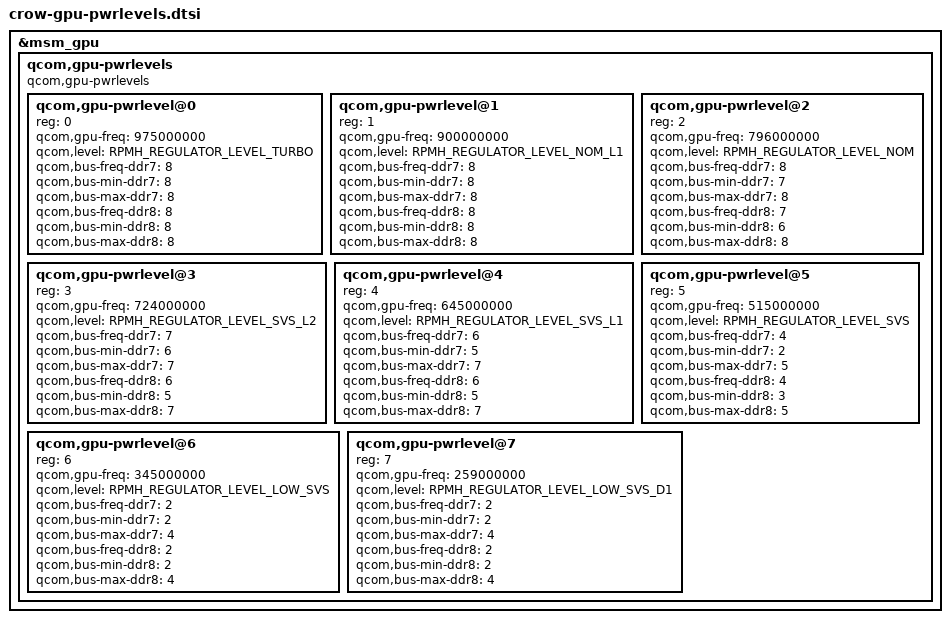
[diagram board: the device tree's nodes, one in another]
&msm_gpu {
	/* Power levels */
	qcom,gpu-pwrlevels {
		compatible="qcom,gpu-pwrlevels";

		#address-cells = <1>;
		#size-cells = <0>;

		qcom,gpu-pwrlevel@0 {
			reg = <0>;
			qcom,gpu-freq = <975000000>;
			qcom,level = <RPMH_REGULATOR_LEVEL_TURBO>;

			qcom,bus-freq-ddr7 = <8>;
			qcom,bus-min-ddr7 = <8>;
			qcom,bus-max-ddr7 = <8>;

			qcom,bus-freq-ddr8 = <8>;
			qcom,bus-min-ddr8 = <8>;
			qcom,bus-max-ddr8 = <8>;
		};

		qcom,gpu-pwrlevel@1 {
			reg = <1>;
			qcom,gpu-freq = <900000000>;
			qcom,level = <RPMH_REGULATOR_LEVEL_NOM_L1>;

			qcom,bus-freq-ddr7 = <8>;
			qcom,bus-min-ddr7 = <8>;
			qcom,bus-max-ddr7 = <8>;

			qcom,bus-freq-ddr8 = <8>;
			qcom,bus-min-ddr8 = <8>;
			qcom,bus-max-ddr8 = <8>;
		};

		qcom,gpu-pwrlevel@2 {
			reg = <2>;
			qcom,gpu-freq = <796000000>;
			qcom,level = <RPMH_REGULATOR_LEVEL_NOM>;

			qcom,bus-freq-ddr7 = <8>;
			qcom,bus-min-ddr7 = <7>;
			qcom,bus-max-ddr7 = <8>;

			qcom,bus-freq-ddr8 = <7>;
			qcom,bus-min-ddr8 = <6>;
			qcom,bus-max-ddr8 = <8>;
		};

		qcom,gpu-pwrlevel@3 {
			reg = <3>;
			qcom,gpu-freq = <724000000>;
			qcom,level = <RPMH_REGULATOR_LEVEL_SVS_L2>;

			qcom,bus-freq-ddr7 = <7>;
			qcom,bus-min-ddr7 = <6>;
			qcom,bus-max-ddr7 = <7>;

			qcom,bus-freq-ddr8 = <6>;
			qcom,bus-min-ddr8 = <5>;
			qcom,bus-max-ddr8 = <7>;
		};

		qcom,gpu-pwrlevel@4 {
			reg = <4>;
			qcom,gpu-freq = <645000000>;
			qcom,level = <RPMH_REGULATOR_LEVEL_SVS_L1>;

			qcom,bus-freq-ddr7 = <6>;
			qcom,bus-min-ddr7 = <5>;
			qcom,bus-max-ddr7 = <7>;

			qcom,bus-freq-ddr8 = <6>;
			qcom,bus-min-ddr8 = <5>;
			qcom,bus-max-ddr8 = <7>;
		};

		qcom,gpu-pwrlevel@5 {
			reg = <5>;
			qcom,gpu-freq = <515000000>;
			qcom,level = <RPMH_REGULATOR_LEVEL_SVS>;

			qcom,bus-freq-ddr7 = <4>;
			qcom,bus-min-ddr7 = <2>;
			qcom,bus-max-ddr7 = <5>;

			qcom,bus-freq-ddr8 = <4>;
			qcom,bus-min-ddr8 = <3>;
			qcom,bus-max-ddr8 = <5>;
		};

		qcom,gpu-pwrlevel@6 {
			reg = <6>;
			qcom,gpu-freq = <345000000>;
			qcom,level = <RPMH_REGULATOR_LEVEL_LOW_SVS>;

			qcom,bus-freq-ddr7 = <2>;
			qcom,bus-min-ddr7 = <2>;
			qcom,bus-max-ddr7 = <4>;

			qcom,bus-freq-ddr8 = <2>;
			qcom,bus-min-ddr8 = <2>;
			qcom,bus-max-ddr8 = <4>;
		};

		qcom,gpu-pwrlevel@7 {
			reg = <7>;
			qcom,gpu-freq = <259000000>;
			qcom,level = <RPMH_REGULATOR_LEVEL_LOW_SVS_D1>;

			qcom,bus-freq-ddr7 = <2>;
			qcom,bus-min-ddr7 = <2>;
			qcom,bus-max-ddr7 = <4>;

			qcom,bus-freq-ddr8 = <2>;
			qcom,bus-min-ddr8 = <2>;
			qcom,bus-max-ddr8 = <4>;
		};
	};
};
